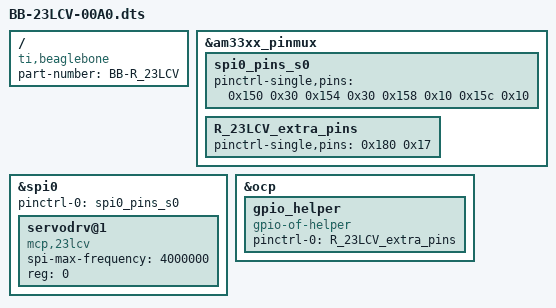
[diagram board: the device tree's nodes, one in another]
/dts-v1/;
/plugin/;

/* SPI RAM */

/ {
    compatible = "ti,beaglebone", "ti,beaglebone-black";

    /* identification */
    part-number = "BB-R_23LCV";

    fragment@0 {
        target = <&am33xx_pinmux>;
        __overlay__ {
            spi0_pins_s0: spi0_pins_s0 {
                        pinctrl-single,pins = <
                                0x150 0x30      /* P9_22 spi0_sclk, INPUT_PULLUP | MODE0 */
                                0x154 0x30      /* P9_21 spi0_d0, INPUT_PULLUP | MODE0 */
                                0x158 0x10      /* P9_18 spi0_d1, OUTPUT_PULLUP | MODE0 */
                                0x15c 0x10      /* P9_17 spi0_cs0, OUTPUT_PULLUP | MODE0 */
                >;
            };
        };
    };
    fragment@1 {
        target = <&am33xx_pinmux>;
        __overlay__ {
            R_23LCV_extra_pins: R_23LCV_extra_pins {
                        pinctrl-single,pins = <
                                0x180 0x17      /* P9_26 gpio, OUTPUT PULLDOWN | MODE7 for alternate cs */
                >;
            };
        };
    };
    
    fragment@2 {
        target = <&spi0>;
        __overlay__ {

             #address-cells = <1>;
             #size-cells = <0>;
             status = "okay";
             pinctrl-names = "default";
             pinctrl-0 = <&spi0_pins_s0>;

             servodrv@1 {
                 spi-max-frequency = <4000000>;
                 reg = <0>;
                 compatible = "mcp,23lcv";
            };
        };
    };

    fragment@3 {
		target = <&ocp>;
		__overlay__ {
			gpio_helper {
				compatible = "gpio-of-helper";
				status = "okay";
				pinctrl-names = "default";
				pinctrl-0 = <&R_23LCV_extra_pins>;
			};
		};
	};
};
